# ATmega162 register map
Vendor: Atmel; File version: 1.0
CPU: other r0p0, little endian, no MPU, no FPU, 4 interrupt priority bits
Registers are 8-bit, read-write, reset 0x0 unless marked. A register's access mark holds for its fields unless they carry their own. Offsets are from the block's base; [hi:lo] are bit positions.

## TC0 — Timer/Counter, 8-bit
Base 0x00000051
0x00 OCR0 — Timer/Counter 0 Output Compare Register
0x01 TCNT0 — Timer/Counter 0 Register
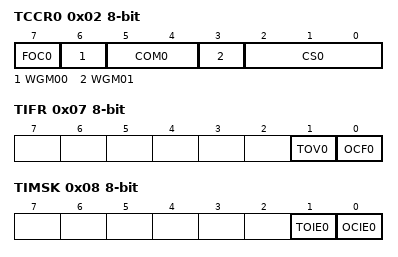
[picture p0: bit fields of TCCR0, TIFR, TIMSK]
0x02 TCCR0 — Timer/Counter 0 Control Register
  [7] FOC0 — Force Output Compare
  [6] WGM00 — Waveform Generation Mode 0
    0=NORMAL; 1=CTC
  [5:4] COM0 — Compare Match Output Modes
  [3] WGM01 — Waveform Generation Mode 1
  [2:0] CS0 — Clock Selects
    0=NO_CLOCK_SOURCE_STOPPED; 1=RUNNING_NO_PRESCALING; 2=RUNNING_CLK_8; 3=RUNNING_CLK_64; 4=RUNNING_CLK_256; 5=RUNNING_CLK_1024; 6=RUNNING_EXTCLK_TN_FALLING_EDGE; 7=RUNNING_EXTCLK_TN_RISING_EDGE
0x07 TIFR — Timer/Counter Interrupt Flag register
  [1] TOV0 — Timer/Counter0 Overflow Flag
  [0] OCF0 — Output Compare Flag 0
0x08 TIMSK — Timer/Counter Interrupt Mask Register
  [1] TOIE0 — Timer/Counter0 Overflow Interrupt Enable
  [0] OCIE0 — Timer/Counter0 Output Compare Match Interrupt register

## TC1 — Timer/Counter, 16-bit
Base 0x00000044
0x00 ICR1 16-bit (reset mask 0xFF) — Timer/Counter1 Input Capture Register Bytes
0x04 OCR1B 16-bit (reset mask 0xFF) — Timer/Counter1 Output Compare Register B Bytes
0x06 OCR1A 16-bit (reset mask 0xFF) — Timer/Counter1 Output Compare Register A Bytes
0x08 TCNT1 16-bit (reset mask 0xFF) — Timer/Counter1 Bytes
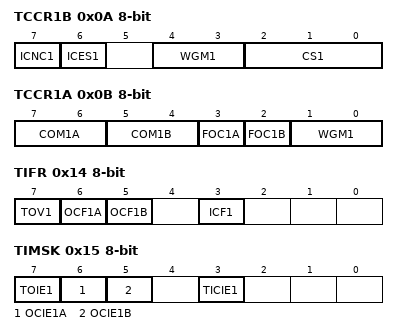
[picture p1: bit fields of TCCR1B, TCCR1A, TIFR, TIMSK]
0x0A TCCR1B — Timer/Counter1 Control Register B
  [7] ICNC1 — Input Capture 1 Noise Canceler
  [6] ICES1 — Input Capture 1 Edge Select
  [4:3] WGM1 — Pulse Width Modulator Select Bits
  [2:0] CS1 — Clock Select1 bits
    0=NO_CLOCK_SOURCE_STOPPED; 1=RUNNING_NO_PRESCALING; 2=RUNNING_CLK_8; 3=RUNNING_CLK_64; 4=RUNNING_CLK_256; 5=RUNNING_CLK_1024; 6=RUNNING_EXTCLK_TN_FALLING_EDGE; 7=RUNNING_EXTCLK_TN_RISING_EDGE
0x0B TCCR1A — Timer/Counter1 Control Register A
  [7:6] COM1A — Compare Output Mode 1A, bits
  [5:4] COM1B — Compare Output Mode 1B, bits
  [3] FOC1A — Force Output Compare for Channel A
  [2] FOC1B — Force Output Compare for Channel B
  [1:0] WGM1 — Pulse Width Modulator Select Bits
0x14 TIFR — Timer/Counter Interrupt Flag register
  [7] TOV1 — Timer/Counter1 Overflow Flag
  [6] OCF1A — Output Compare Flag 1A
  [5] OCF1B — Output Compare Flag 1B
  [3] ICF1 — Input Capture Flag 1
0x15 TIMSK — Timer/Counter Interrupt Mask Register
  [7] TOIE1 — Timer/Counter1 Overflow Interrupt Enable
  [6] OCIE1A — Timer/Counter1 Output CompareA Match Interrupt Enable
  [5] OCIE1B — Timer/Counter1 Output CompareB Match Interrupt Enable
  [3] TICIE1 — Timer/Counter1 Input Capture Interrupt Enable

## TC2 — Timer/Counter, 8-bit Async
Base 0x00000042
0x00 OCR2 — Output Compare Register
0x01 TCNT2 — Timer/Counter Register
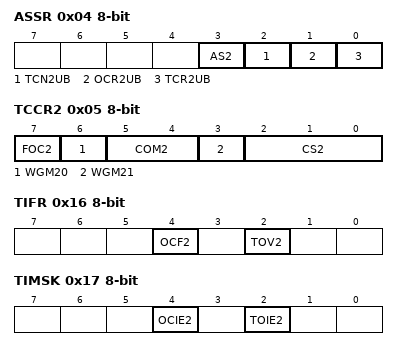
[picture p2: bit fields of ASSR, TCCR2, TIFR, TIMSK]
0x04 ASSR — Asynchronous Status Register
  [3] AS2 — Asynchronous Timer 2
  [2] TCN2UB — Timer/Counter2 Update Busy
  [1] OCR2UB — Output Compare Register2 Update Busy
  [0] TCR2UB — Timer/Counter Control Register2 Update Busy
0x05 TCCR2 — Timer/Counter Control Register
  [7] FOC2 — Force Output Compare
  [6] WGM20 — Pulse Width Modulator Select Bit 0
    0=NORMAL; 1=CTC
  [5:4] COM2 — Compare Match Output Mode
  [3] WGM21 — Pulse Width Modulator Select Bit 1
  [2:0] CS2 — Clock Select
    0=NO_CLOCK_SOURCE_STOPPED; 1=RUNNING_NO_PRESCALING; 2=RUNNING_CLK_8; 3=RUNNING_CLK_32; 4=RUNNING_CLK_64; 5=RUNNING_CLK_128; 6=RUNNING_CLK_256; 7=RUNNING_CLK_1024
0x16 TIFR — Timer/Counter Interrupt Flag Register
  [4] OCF2 — Output Compare Flag 2
  [2] TOV2 — Timer/Counter2 Overflow Flag
0x17 TIMSK — Timer/Counter Interrupt Mask Register
  [4] OCIE2 — Timer/Counter2 Output Compare Match Interrupt Enable
  [2] TOIE2 — Timer/Counter2 Overflow Interrupt Enable

## TC3 — Timer/Counter, 16-bit
Base 0x0000007C
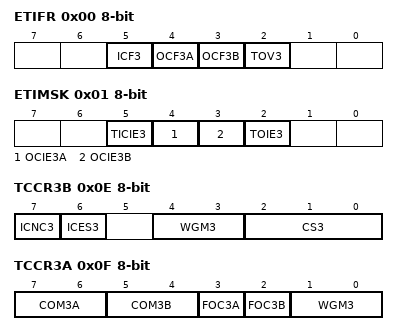
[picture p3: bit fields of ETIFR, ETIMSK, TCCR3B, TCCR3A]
0x00 ETIFR — Extended Timer/Counter Interrupt Flag register
  [5] ICF3 — Input Capture Flag 3
  [4] OCF3A — Output Compare Flag 3A
  [3] OCF3B — Output Compare Flag 3B
  [2] TOV3 — Timer/Counter3 Overflow Flag
0x01 ETIMSK — Extended Timer/Counter Interrupt Mask Register
  [5] TICIE3 — Timer/Counter3 Input Capture Interrupt Enable
  [4] OCIE3A — Timer/Counter3 Output CompareA Match Interrupt Enable
  [3] OCIE3B — Timer/Counter3 Output CompareB Match Interrupt Enable
  [2] TOIE3 — Timer/Counter3 Overflow Interrupt Enable
0x04 ICR3 16-bit (reset mask 0xFF) — Timer/Counter3 Input Capture Register Bytes
0x08 OCR3B 16-bit (reset mask 0xFF) — Timer/Counter3 Output Compare Register B Bytes
0x0A OCR3A 16-bit (reset mask 0xFF) — Timer/Counter3 Output Compare Register A Bytes
0x0C TCNT3 16-bit (reset mask 0xFF) — Timer/Counter3 Bytes
0x0E TCCR3B — Timer/Counter3 Control Register B
  [7] ICNC3 — Input Capture 3 Noise Canceler
  [6] ICES3 — Input Capture 3 Edge Select
  [4:3] WGM3 — Pulse Width Modulator Select Bits
  [2:0] CS3 — Clock Select3 bits
    0=NO_CLOCK_SOURCE_STOPPED; 1=RUNNING_NO_PRESCALING; 2=RUNNING_CLK_8; 3=RUNNING_CLK_64; 4=RUNNING_CLK_256; 5=RUNNING_CLK_1024; 6=RUNNING_CLK_16; 7=RUNNING_CLK_32
0x0F TCCR3A — Timer/Counter3 Control Register A
  [7:6] COM3A — Compare Output Mode 3A, bits
  [5:4] COM3B — Compare Output Mode 3B, bits
  [3] FOC3A — Force Output Compare for Channel A
  [2] FOC3B — Force Output Compare for Channel B
  [1:0] WGM3 — Pulse Width Modulator Select Bits

## USART0 — USART
Base 0x00000029
0x00 UBRR0L — USART Baud Rate Register Low Byte
  [7:0] UBRR0 — USART Baud Rate Register Low bits
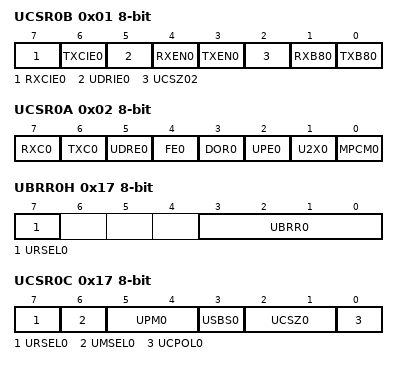
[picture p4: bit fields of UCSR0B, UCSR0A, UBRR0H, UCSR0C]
0x01 UCSR0B — USART Control and Status Register B
  [7] RXCIE0 — RX Complete Interrupt Enable
  [6] TXCIE0 — TX Complete Interrupt Enable
  [5] UDRIE0 — USART Data register Empty Interrupt Enable
  [4] RXEN0 — Receiver Enable
  [3] TXEN0 — Transmitter Enable
  [2] UCSZ02 — Character Size
  [1] RXB80 — Receive Data Bit 8
  [0] TXB80 — Transmit Data Bit 8
0x02 UCSR0A — USART Control and Status Register A
  [7] RXC0 — USART Receive Complete
  [6] TXC0 — USART Transmit Complete
  [5] UDRE0 — USART Data Register Empty
  [4] FE0 — Framing Error
  [3] DOR0 — Data overRun
  [2] UPE0 — Parity Error
  [1] U2X0 — Double the USART transmission speed
  [0] MPCM0 — Multi-processor Communication Mode
0x03 UDR0 — USART I/O Data Register
0x17 UBRR0H — USART Baud Rate Register High Byte
  [7] URSEL0 — Register Select
  [3:0] UBRR0 — USART Baud Rate Register High bits
0x17 UCSR0C — USART Control and Status Register C
  [7] URSEL0 — Register Select
  [6] UMSEL0 — USART Mode Select
    0=ASYNCHRONOUS_OPERATION; 1=SYNCHRONOUS_OPERATION
  [5:4] UPM0 — Parity Mode Bits
    0=DISABLED; 2=ENABLED_EVEN_PARITY; 3=ENABLED_ODD_PARITY
  [3] USBS0 — Stop Bit Select
    0=1_BIT; 1=2_BIT
  [2:1] UCSZ0 — Character Size
  [0] UCPOL0 — Clock Polarity

## USART1 — USART
Base 0x00000020
0x00 UBRR1L — USART Baud Rate Register Low Byte
  [7:0] UBRR1 — USART Baud Rate Register Low bits
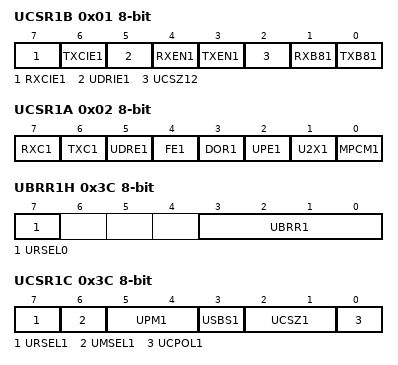
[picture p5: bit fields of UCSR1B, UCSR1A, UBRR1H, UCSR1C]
0x01 UCSR1B — USART Control and Status Register B
  [7] RXCIE1 — RX Complete Interrupt Enable
  [6] TXCIE1 — TX Complete Interrupt Enable
  [5] UDRIE1 — USART Data register Empty Interrupt Enable
  [4] RXEN1 — Receiver Enable
  [3] TXEN1 — Transmitter Enable
  [2] UCSZ12 — Character Size
  [1] RXB81 — Receive Data Bit 8
  [0] TXB81 — Transmit Data Bit 8
0x02 UCSR1A — USART Control and Status Register A
  [7] RXC1 — USART Receive Complete
  [6] TXC1 — USART Transmit Complete
  [5] UDRE1 — USART Data Register Empty
  [4] FE1 — Framing Error
  [3] DOR1 — Data overRun
  [2] UPE1 — Parity Error
  [1] U2X1 — Double the USART transmission speed
  [0] MPCM1 — Multi-processor Communication Mode
0x03 UDR1 — USART I/O Data Register
0x3C UBRR1H — USART Baud Rate Register High Byte
  [7] URSEL0 — Register Select
  [3:0] UBRR1 — USART Baud Rate Register High bits
0x3C UCSR1C — USART Control and Status Register C
  [7] URSEL1 — Register Select
  [6] UMSEL1 — USART Mode Select
    0=ASYNCHRONOUS_OPERATION; 1=SYNCHRONOUS_OPERATION
  [5:4] UPM1 — Parity Mode Bits
    0=DISABLED; 2=ENABLED_EVEN_PARITY; 3=ENABLED_ODD_PARITY
  [3] USBS1 — Stop Bit Select
    0=1_BIT; 1=2_BIT
  [2:1] UCSZ1 — Character Size
  [0] UCPOL1 — Clock Polarity

## WDT — Watchdog Timer
Base 0x00000041
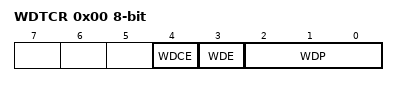
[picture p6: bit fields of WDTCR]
0x00 WDTCR — Watchdog Timer Control Register
  [4] WDCE — Watchdog Change Enable
  [3] WDE — Watch Dog Enable
  [2:0] WDP — Watch Dog Timer Prescaler bits
    0=OSCILLATOR_CYCLES_16K; 1=OSCILLATOR_CYCLES_32K; 2=OSCILLATOR_CYCLES_64K; 3=OSCILLATOR_CYCLES_128K; 4=OSCILLATOR_CYCLES_256K; 5=OSCILLATOR_CYCLES_512K; 6=OSCILLATOR_CYCLES_1024K; 7=OSCILLATOR_CYCLES_2048K
